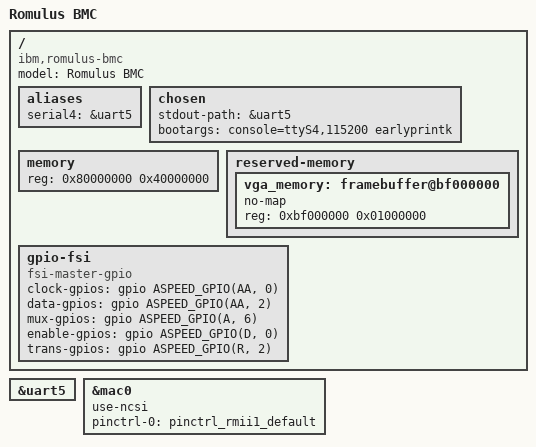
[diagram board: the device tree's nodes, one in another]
/dts-v1/;

#include "aspeed-g5.dtsi"

/ {
	model = "Romulus BMC";
	compatible = "ibm,romulus-bmc", "aspeed,ast2500";

	aliases {
		serial4 = &uart5;
	};

	chosen {
		stdout-path = &uart5;
		bootargs = "console=ttyS4,115200 earlyprintk";
	};

	memory {
		reg = <0x80000000 0x40000000>;
	};

	reserved-memory {
		#address-cells = <1>;
		#size-cells = <1>;
		ranges;

		vga_memory: framebuffer@bf000000 {
			no-map;
			reg = <0xbf000000 0x01000000>; /* 16M */
		};
	};

	gpio-fsi {
		compatible = "fsi-master-gpio", "fsi-master";

		status = "okay";

		clock-gpios = <&gpio ASPEED_GPIO(AA, 0) GPIO_ACTIVE_HIGH>;
		data-gpios = <&gpio ASPEED_GPIO(AA, 2) GPIO_ACTIVE_HIGH>;
		mux-gpios = <&gpio ASPEED_GPIO(A, 6) GPIO_ACTIVE_HIGH>;
		enable-gpios = <&gpio ASPEED_GPIO(D, 0) GPIO_ACTIVE_HIGH>;
		trans-gpios = <&gpio ASPEED_GPIO(R, 2) GPIO_ACTIVE_HIGH>;
	};
};

&uart5 {
	status = "okay";
};

&mac0 {
	status = "okay";

	use-ncsi;

	pinctrl-names = "default";
	pinctrl-0 = <&pinctrl_rmii1_default>;
};
